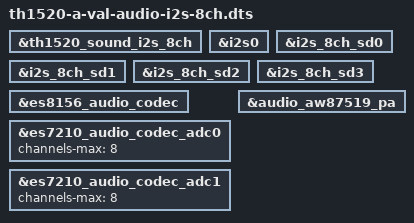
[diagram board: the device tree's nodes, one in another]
/* SPDX-License-Identifier: GPL-2.0 */
/*
 * Copyright (C) 2021 Alibaba Group Holding Limited.
 */

#include "th1520-a-val.dtsi"

&th1520_sound_i2s_8ch {
	status = "okay";
};

&i2s0 {
	status = "okay";
};

&i2s_8ch_sd0 {
	status = "okay";
};

&i2s_8ch_sd1 {
	status = "okay";
};

&i2s_8ch_sd2 {
	status = "okay";
};

&i2s_8ch_sd3 {
	status = "okay";
};

&es8156_audio_codec {
	status = "okay";
};

&es7210_audio_codec_adc0 {
	status = "okay";
	channels-max = <8>;
};

&es7210_audio_codec_adc1 {
	status = "okay";
	channels-max = <8>;
};

&audio_aw87519_pa {
	status = "okay";
};
